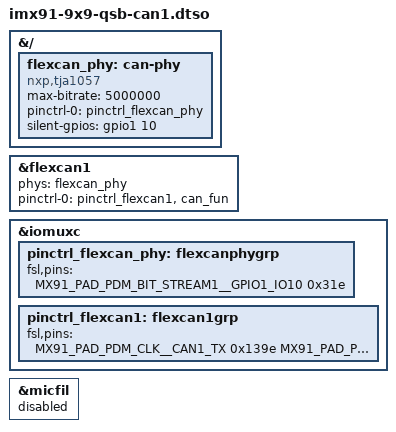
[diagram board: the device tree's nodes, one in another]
// SPDX-License-Identifier: (GPL-2.0+ OR MIT)
/*
 * Copyright 2026 NXP
 */

#include <dt-bindings/gpio/gpio.h>
#include "imx91-pinfunc.h"

/dts-v1/;
/plugin/;

&{/} {
	flexcan_phy: can-phy {
		compatible = "nxp,tja1057";
		#phy-cells = <0>;
		max-bitrate = <5000000>;
		pinctrl-names = "default";
		pinctrl-0 = <&pinctrl_flexcan_phy>;
		silent-gpios = <&gpio1 10 GPIO_ACTIVE_HIGH>;
	};
};

&flexcan1 {
	phys = <&flexcan_phy>;
	pinctrl-names = "default";
	pinctrl-0 = <&pinctrl_flexcan1>, <&can_fun>;
	status = "okay";
};

&iomuxc {
	pinctrl_flexcan_phy: flexcanphygrp {
		fsl,pins = <
			MX91_PAD_PDM_BIT_STREAM1__GPIO1_IO10	0x31e
		>;
	};

	pinctrl_flexcan1: flexcan1grp {
		fsl,pins = <
			MX91_PAD_PDM_CLK__CAN1_TX		0x139e
			MX91_PAD_PDM_BIT_STREAM0__CAN1_RX	0x139e
		>;
	};
};

/* micfil uses PDM port A pins, conflicts with can1 */
&micfil {
	status = "disabled";
};
